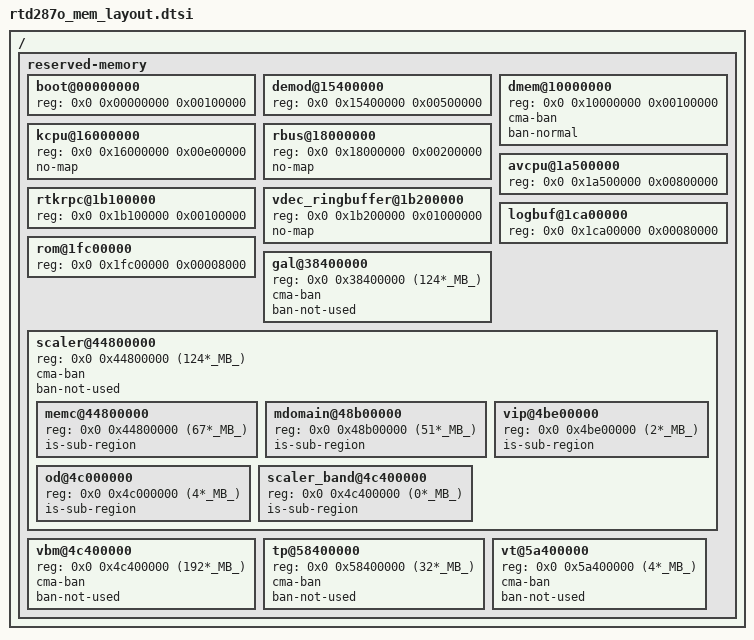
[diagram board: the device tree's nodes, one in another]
/*
 * rtd287o memory layout
 */

#define _MB_ 1024*1024

/ {

	reserved-memory {
		#address-cells = <2>;
		#size-cells = <1>;
		ranges;

		boot@00000000 {
			reg = <0x0 0x00000000 0x00100000>;
		};

		demod@15400000 {
			reg = <0x0 0x15400000 0x00500000>;
            /*
			cma-ban;
			ban-not-used;
            */
		};

		dmem@10000000 {
			reg = <0x0 0x10000000 0x00100000>;
			cma-ban;
			ban-normal;
		};

		/* for secure os */
		kcpu@16000000 {
			reg = <0x0 0x16000000 0x00e00000>;
			no-map;
		};

		rbus@18000000 {
			reg = <0x0 0x18000000 0x00200000>;
			no-map;
		};

		avcpu@1a500000 {
			reg = <0x0 0x1a500000 0x00800000>;
		};

		/*used for atf and rpc buffer*/
		rtkrpc@1b100000 {
			reg = <0x0 0x1b100000 0x00100000>;
		};

		vdec_ringbuffer@1b200000 {
			reg = <0x0 0x1b200000 0x01000000>;
			no-map;
		};

		logbuf@1ca00000 {
			reg = <0x0 0x1ca00000 0x00080000>;
		};

		rom@1fc00000 {
			reg = <0x0 0x1fc00000 0x00008000>;
		};

		gal@38400000 {
			reg = <0x0 0x38400000 (124*_MB_)>;
			cma-ban;
			ban-not-used;
		};

		scaler@44800000 {
			reg = <0x0 0x44800000 (124*_MB_)>;
			cma-ban;
			ban-not-used;

			memc@44800000 {
				reg = <0x0 0x44800000 (67*_MB_)>;
				is-sub-region;
			};

			mdomain@48b00000 {
				reg = <0x0 0x48b00000 (51*_MB_)>;
				is-sub-region;
			};

			vip@4be00000 {
				reg = <0x0 0x4be00000 (2*_MB_)>;
				is-sub-region;
			};

			od@4c000000 {
				reg = <0x0 0x4c000000 (4*_MB_)>;
				is-sub-region;
			};

			scaler_band@4c400000 {
				reg = <0x0 0x4c400000 (0*_MB_)>;
				is-sub-region;
			};
		};

		vbm@4c400000 {
			reg = <0x0 0x4c400000 (192*_MB_)>;
			cma-ban;
			ban-not-used;
		};

		tp@58400000 {
			reg = <0x0 0x58400000 (32*_MB_)>;
			cma-ban;
			ban-not-used;
		}; 

		vt@5a400000 {
			reg = <0x0 0x5a400000 (4*_MB_)>;
			cma-ban;
			ban-not-used;
		}; 
	};
};
